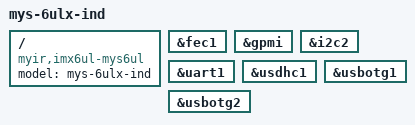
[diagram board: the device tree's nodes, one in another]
/dts-v1/;

#include <arm/imx6ul.dtsi>
#include "imx6ul-myir-mys6ul.dtsi"

/ {
	model = "mys-6ulx-ind";
	compatible = "myir,imx6ul-mys6ul", "fsl,imx6ul";
};

&fec1 {
	status = "okay";
};

&gpmi {
	status = "okay";
};

&i2c2 {
	status = "okay";
};

&uart1 {
	status = "okay";
};

&usdhc1 {
	status = "okay";
};

&usbotg1 {
	status = "okay";
};

&usbotg2 {
	status = "okay";
};
